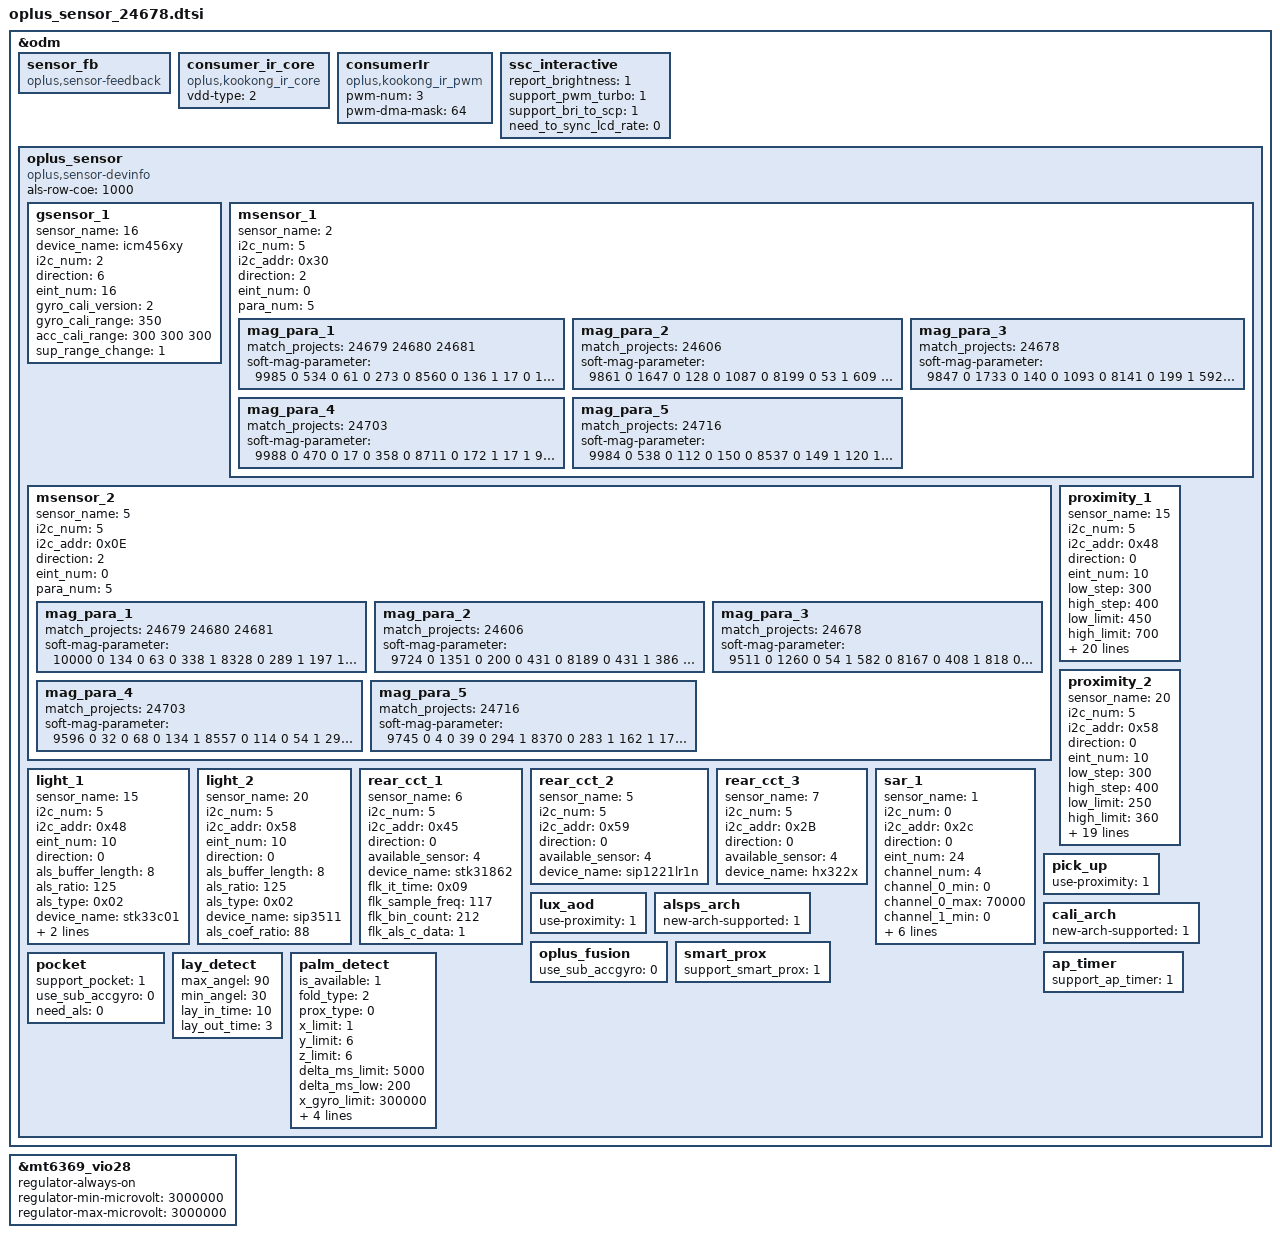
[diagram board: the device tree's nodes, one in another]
&odm {
	sensor_fb: sensor_fb {
		compatible = "oplus,sensor-feedback";
	};
	consumer_ir_core: consumer_ir_core {
		compatible = "oplus,kookong_ir_core";
		status = "okay";
		vdd-type = <2>;  /*0: internal LDO , 1: external LDO , 2: NO VDD */
	};
	consumerIr: consumerIr {
		compatible = "oplus,kookong_ir_pwm";
		status = "okay";
		pwm-num = <3>;
		pwm-dma-mask = <64>;
	};
	ssc_interactive: ssc_interactive {
		report_brightness = <1>;
		support_pwm_turbo = <1>;
		support_bri_to_scp = <1>;
		need_to_sync_lcd_rate = <0>;
	};
	oplus_sensor:oplus_sensor {
		compatible = "oplus,sensor-devinfo";
		als-row-coe = <1000>;
		/* sensor start */
		/*
		enum {
			LIS3DH,
			LSM6DS3,
			BMI160,
			LIS2HH12,
			LSM6DSM,
			BMI2XY,
			LSM6DSO,
			ICM4X6XX,
			ICM4263X,
			ICM4N607,
			BMI22X,
			SC7A20,
			MC34X9,
		};
		*/
		gsensor_1: gsensor_1 {
			status = "okay";
			sensor_name = <16>; // ICM456XY
			device_name = "icm456xy";
			i2c_num = <2>;
			direction = <6>;
			eint_num = <16>;
			gyro_cali_version= <2>;
			gyro_cali_range =<350>;
			acc_cali_range= <300 300 300>;
			sup_range_change = <1>;
		};

		/*
		enum {
			AKM09911,
			MMC3530,
			MMC5603,
			MXG4300,
			AKM09918,
			AKM09919,
		};
		*/
		msensor_1: msensor_1 {
			status = "okay";
			sensor_name = <2>; // MMC5603
			i2c_num = <5>;
			i2c_addr = <0x30>;
			direction = <2>;
			eint_num = <0>;
			para_num = <5>;
			mag_para_1 {
				match_projects = <24679 24680 24681>;//无NFC
				soft-mag-parameter = <9985 0 534 0 61 0 273 0 8560 0 136 1 17 0 123 0 10061 0>;
			};
			mag_para_2 {
				match_projects = <24606>;//NFC
				soft-mag-parameter = <9861 0 1647 0 128 0 1087 0 8199 0 53 1 609 0 874 1 10060 0>;
			};
			mag_para_3 {
				match_projects = <24678>;//NFC and SAR
				soft-mag-parameter = <9847 0 1733 0 140 0 1093 0 8141 0 199 1 592 0 782 1 10006 0>;
			};
			mag_para_4 {
				match_projects = <24703>;
				soft-mag-parameter = <9988 0 470 0 17 0 358 0 8711 0 172 1 17 1 9 1 10255 0>;
			};
			mag_para_5 {
				match_projects = <24716>;
				soft-mag-parameter = <9984 0 538 0 112 0 150 0 8537 0 149 1 120 1 127 1 10130 0>;
			};
		};
		msensor_2: msensor_2 {
			status = "okay";
			sensor_name = <5>; // AKM09919
			i2c_num = <5>;
			i2c_addr = <0x0E>;
			direction = <2>;
			eint_num = <0>;
			para_num = <5>;
			mag_para_1 {
				match_projects = <24679 24680 24681>;//无NFC
				soft-mag-parameter = <10000 0 134 0 63 0 338 1 8328 0 289 1 197 1 285 1 11281 0>;
			};
			mag_para_2 {
				match_projects = <24606>;//NFC
				soft-mag-parameter = <9724 0 1351 0 200 0 431 0 8189 0 431 1 386 0 702 1 11332 0>;
			};
			mag_para_3 {
				match_projects = <24678>;//NFC and SAR
				soft-mag-parameter = <9511 0 1260 0 54 1 582 0 8167 0 408 1 818 0 842 1 11224 0>;
			};
			mag_para_4 {
				match_projects = <24703>;
				soft-mag-parameter = <9596 0 32 0 68 0 134 1 8557 0 114 0 54 1 291 1 11305 0>;
			};
			mag_para_5 {
				match_projects = <24716>;
				soft-mag-parameter = <9745 0 4 0 39 0 294 1 8370 0 283 1 162 1 170 1 11645 0>;
			};
		};
		/*
		enum {
			TMD2725,
			APSD9922,
			STK3335,
			STK3331,
			STK2232,
			TCS3701,
			STK32600,
			STK33502,
			MN78911,
			TCS3720,
			SIP3515,
			STK3329,
			LTR569,
			SIP3510,
			SIP3625,
			STK33C01,
			SIP3535,
			STK63701,
			TMD2765,
			TCS3743,
			SIP3511,
		};
		*/
		proximity_1: proximity_1 {
			status = "okay";
			sensor_name = <15>; // STK33C01
			i2c_num = <5>;
			i2c_addr = <0x48>;
			direction = <0>;
			eint_num = <10>;
			low_step = <300>;
			high_step = <400>;
			low_limit = <450>;
			high_limit = <700>;
			dirty_low_step = <500>;
			dirty_high_step = <600>;
			ps_dirty_limit = <1800>;
			ps_ir_limit = <500>;
			ps_adjust_min = <0>;
			ps_adjust_max = <1850>;
			sampling_count = <5>;
			step_max = <500>;
			step_min = <100>;
			step_div = <2000>;
			anti_shake_delta = <120>;
			dynamic_cali_max = <3000>;
			raw2offset_radio = <1000>;
			offset_max = <15000>;
			offset_range_min = <0>;
			offset_range_max = <65534>;
			force_cali_limit = <2000>;
			cali_jitter_limit = <40>;
			cal_offset_margin = <3000>;
			sensor-reg = <0x01 0x44 0x03 0x5C 0x05 0x41>;
		};
		proximity_2: proximity_2 {
			status = "okay";
			sensor_name = <20>; // SIP3511
			i2c_num = <5>;
			i2c_addr = <0x58>;
			direction = <0>;
			eint_num = <10>;
			low_step = <300>;
			high_step = <400>;
			low_limit = <250>;
			high_limit = <360>;
			dirty_low_step = <150>;
			dirty_high_step = <200>;
			ps_dirty_limit = <800>;
			ps_ir_limit = <500>;
			ps_adjust_min = <0>;
			ps_adjust_max = <1850>;
			sampling_count = <5>;
			step_max = <400>;
			step_min = <100>;
			step_div = <2000>;
			anti_shake_delta = <50>;
			dynamic_cali_max = <3000>;
			raw2offset_radio = <1000>;
			offset_max = <15000>;
			offset_range_min = <0>;
			offset_range_max = <65534>;
			force_cali_limit = <2000>;
			cali_jitter_limit = <40>;
			cal_offset_margin = <3000>;
		};
		light_1: light_1 {
			status = "okay";
			sensor_name = <15>; // STK33C01
			i2c_num = <5>;
			i2c_addr = <0x48>;
			eint_num = <10>;
			direction = <0>;
			als_buffer_length =<8>;
			als_ratio = <125>;
			als_type = <0x02>; //0x01 CCT_NORMAL 0x02 CCT_WISE
			device_name = "stk33c01";
			als_coef_ratio = <88>;
			als_algo = <1>; // 0: Subtraction method, 1:Division method
		};
		light_2: light_2 {
			status = "okay";
			sensor_name = <20>; // SIP3511
			i2c_num = <5>;
			i2c_addr = <0x58>;
			eint_num = <10>;
			direction = <0>;
			als_buffer_length =<8>;
			als_ratio = <125>;
			als_type = <0x02>; //0x01 CCT_NORMAL 0x02 CCT_WISE
			device_name = "sip3511";
			als_coef_ratio = <88>;
		};
		/*
		enum {
			STK37600,
			MN29005,
			TCS3408,
			TCS3449,
			SIP5009,
			SIP1221LR1N,
			STK31862,
			HX322X,
		};
		*/
		rear_cct_1: rear_cct_1 {
			status = "okay";
			sensor_name = <6>; // STK31862
			i2c_num = <5>;
			i2c_addr = <0x45>;
			direction = <0>;
			available_sensor = <4>; // bit 0: rear als, bit 1: rear cct, bit 2: rear flicker
			device_name = "stk31862";
			flk_it_time = <0x09>; //IT time, IT1056: 0x09
			flk_sample_freq = <117>; // Set according to flk_it_time
			flk_bin_count = <212>; // Set according to flk_it_time + flk_sample_freq
			flk_als_c_data = <1>; // als_data: 0, c_data: 1
		};
		rear_cct_2: rear_cct_2 {
			status = "okay";
			sensor_name = <5>; // SIP1221LR1N
			i2c_num = <5>;
			i2c_addr = <0x59>;
			direction = <0>;
			available_sensor = <4>; // bit 0: rear als, bit 1: rear cct, bit 2: rear flicker
			device_name = "sip1221lr1n";
		};
		rear_cct_3: rear_cct_3 {
			status = "okay";
			sensor_name = <7>; // HX322X
			i2c_num = <5>;
			i2c_addr = <0x2B>;
			direction = <0>;
			available_sensor = <4>; // bit 0: rear als, bit 1: rear cct, bit 2: rear flicker
			device_name = "hx322x";
		};
		/*
		enum {
			SX933x,
			SX937x,
			AW9610X,
		};
		*/
		sar_1: sar_1 {
			status = "okay";
			sensor_name = <1>; // SX937x
			i2c_num = <0>;
			i2c_addr = <0x2c>;
			direction = <0>;
			eint_num = <24>;
			channel_num = <4>;
			channel_0_min = <0>;
			channel_0_max = <70000>;
			channel_1_min = <0>;
			channel_1_max = <70000>;
			channel_2_min = <0>;
			channel_2_max = <70000>;
			channel_3_min = <0>;
			channel_3_max = <70000>;
			reg_table_num = <3>;
		};

		pick_up: pick_up {
			status = "okay";
			use-proximity = <1>;
		};
		lux_aod: lux_aod {
			status = "okay";
			use-proximity = <1>;
		};
		alsps_arch: alsps_arch {
			status = "okay";
			new-arch-supported = <1>;
		};
		cali_arch: cali_arch {
			status = "okay";
			new-arch-supported = <1>;
		};
		oplus_fusion: oplus_fusion {
			status = "okay";
			use_sub_accgyro = <0>;
		};
		smart_prox: smart_prox {
			status = "okay";
			support_smart_prox = <1>;
		};
		ap_timer: ap_timer {
			status = "okay";
			support_ap_timer = <1>;
		};
		pocket: pocket {
			status = "okay";
			support_pocket = <1>;
			use_sub_accgyro = <0>;
			need_als = <0>;
		};
		lay_detect: lay_detect{
			status = "okay";
			max_angel = <90>;
			min_angel = <30>;
			lay_in_time = <10>;
			lay_out_time = <3>;
		};
		palm_detect: palm_detect{
			status = "okay";
			is_available = <1>;
			fold_type = <2>;
			prox_type = <0>;
			x_limit = <1>;
			y_limit = <6>;
			z_limit = <6>;
			delta_ms_limit = <5000>;
			delta_ms_low = <200>;
			x_gyro_limit = <300000>;
			y_gyro_limit = <300000>;
			z_gyro_limit = <300000>;
			move_limit = <8>;
			als_limit = <3>;
		};
	};
/* sensor end */
};

&mt6369_vio28 {
	regulator-always-on;
        regulator-min-microvolt = <3000000>;
        regulator-max-microvolt = <3000000>;
};
